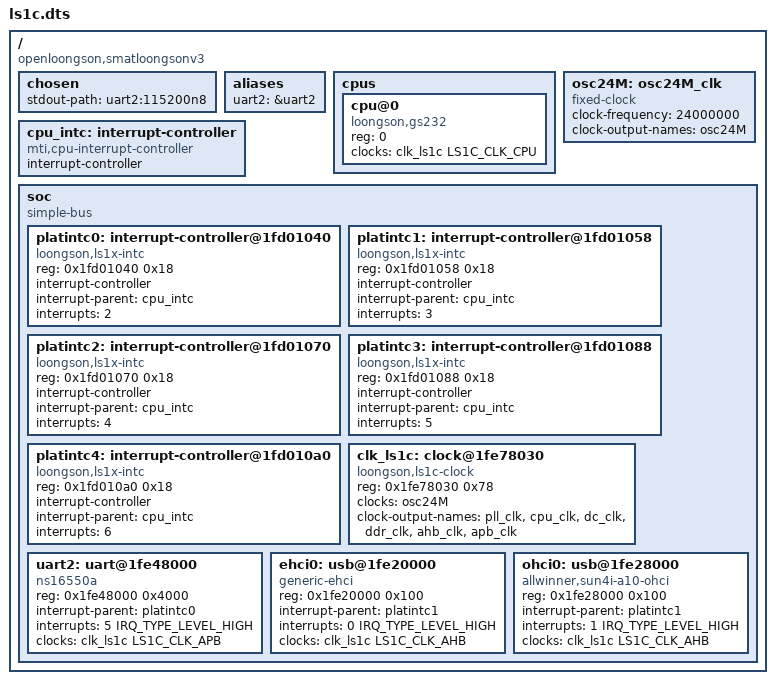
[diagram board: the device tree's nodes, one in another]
// SPDX-License-Identifier: GPL-2.0
/dts-v1/;
#include <dt-bindings/clock/ls1c-clock.h>
#include <dt-bindings/interrupt-controller/irq.h>


/ {
	#address-cells = <1>;
	#size-cells = <1>;
	compatible = "openloongson,smatloongsonv3", "loongson,ls1c300b";

	chosen {
		stdout-path = "uart2:115200n8";
	};

	aliases {
		uart2 = &uart2;
	};

	cpus {
		#address-cells = <1>;
		#size-cells = <0>;

		cpu@0 {
			device_type = "cpu";
			reg = <0>;
			compatible = "loongson,gs232";
			clocks = <&clk_ls1c LS1C_CLK_CPU>;
		};
	};

	osc24M: osc24M_clk {
			#clock-cells = <0>;
			compatible = "fixed-clock";
			clock-frequency = <24000000>;
			clock-output-names = "osc24M";
		};

	cpu_intc: interrupt-controller {
		#address-cells = <0>;
		compatible = "mti,cpu-interrupt-controller";

		interrupt-controller;
		#interrupt-cells = <1>;
	};

	soc {
		#address-cells = <1>;
		#size-cells = <1>;

		compatible = "simple-bus";
		ranges;


		platintc0: interrupt-controller@1fd01040 {
			compatible = "loongson,ls1x-intc";
			reg = <0x1fd01040 0x18>;

			interrupt-controller;
			#interrupt-cells = <2>;

			interrupt-parent = <&cpu_intc>;
			interrupts = <2>;
		};

		platintc1: interrupt-controller@1fd01058 {
			compatible = "loongson,ls1x-intc";
			reg = <0x1fd01058 0x18>;

			interrupt-controller;
			#interrupt-cells = <2>;

			interrupt-parent = <&cpu_intc>;
			interrupts = <3>;
		};

		platintc2: interrupt-controller@1fd01070 {
			compatible = "loongson,ls1x-intc";
			reg = <0x1fd01070 0x18>;

			interrupt-controller;
			#interrupt-cells = <2>;

			interrupt-parent = <&cpu_intc>;
			interrupts = <4>;
		};

		platintc3: interrupt-controller@1fd01088 {
			compatible = "loongson,ls1x-intc";
			reg = <0x1fd01088 0x18>;

			interrupt-controller;
			#interrupt-cells = <2>;

			interrupt-parent = <&cpu_intc>;
			interrupts = <5>;
		};

		platintc4: interrupt-controller@1fd010a0 {
			compatible = "loongson,ls1x-intc";
			reg = <0x1fd010a0 0x18>;

			interrupt-controller;
			#interrupt-cells = <2>;

			interrupt-parent = <&cpu_intc>;
			interrupts = <6>;
		};


		clk_ls1c: clock@1fe78030 {
			compatible = "loongson,ls1c-clock";
			reg = <0x1fe78030 0x78>;

			#clock-cells = <1>;
			clock-names = "osc_clk";
			clocks = <&osc24M>;
			clock-output-names = "pll_clk", "cpu_clk", "dc_clk", "ddr_clk", "ahb_clk", "apb_clk";
		};

		uart2: uart@1fe48000 {
			compatible = "ns16550a";
			reg = <0x1fe48000 0x4000>;

			interrupt-parent = <&platintc0>;
			interrupts = <5 IRQ_TYPE_LEVEL_HIGH>;
			clocks = <&clk_ls1c LS1C_CLK_APB>;
		};

		ehci0: usb@1fe20000 {
			compatible = "generic-ehci";
	   		reg = <0x1fe20000 0x100>;
			interrupt-parent = <&platintc1>;
	   		interrupts = <0 IRQ_TYPE_LEVEL_HIGH>;
	   		clocks = <&clk_ls1c LS1C_CLK_AHB>;
  			};

		ohci0: usb@1fe28000 {
			compatible = "allwinner,sun4i-a10-ohci", "generic-ohci";
			reg = <0x1fe28000 0x100>;
			interrupt-parent = <&platintc1>;
			interrupts = <1 IRQ_TYPE_LEVEL_HIGH>;
			clocks = <&clk_ls1c LS1C_CLK_AHB>;
			};

	};
};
